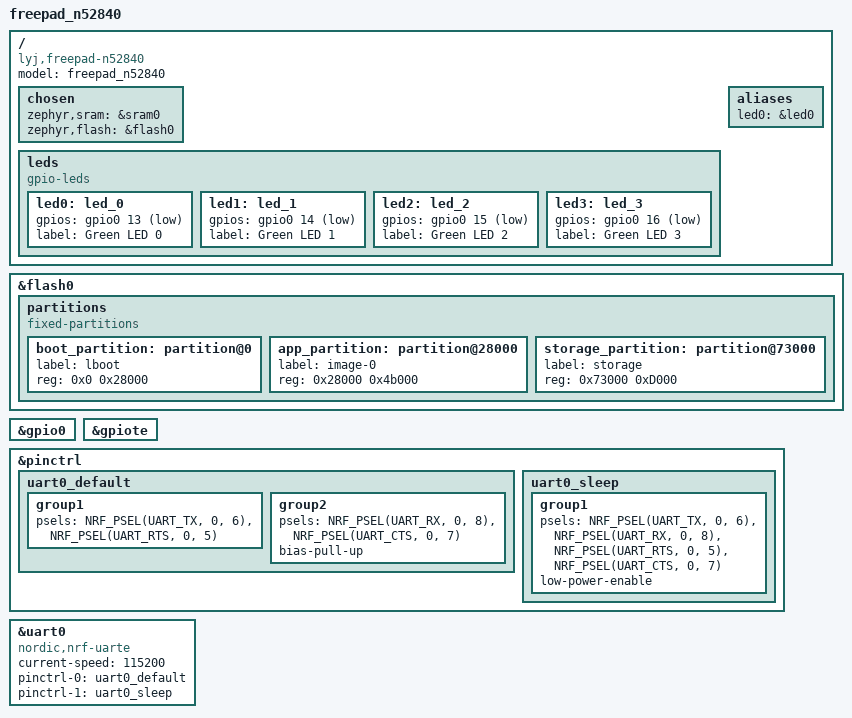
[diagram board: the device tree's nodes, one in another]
// Copyright (c) 2024 Nordic Semiconductor ASA
// SPDX-License-Identifier: Apache-2.0

/dts-v1/;
#include <nordic/nrf52840_qiaa.dtsi>

/ {
	model = "freepad_n52840";
	compatible = "lyj,freepad-n52840";

	chosen {
		zephyr,sram = &sram0;
		zephyr,flash = &flash0;
	};

	leds {
		compatible = "gpio-leds";
		led0: led_0 {
			gpios = <&gpio0 13 GPIO_ACTIVE_LOW>;
			label = "Green LED 0";
		};
		led1: led_1 {
			gpios = <&gpio0 14 GPIO_ACTIVE_LOW>;
			label = "Green LED 1";
		};
		led2: led_2 {
			gpios = <&gpio0 15 GPIO_ACTIVE_LOW>;
			label = "Green LED 2";
		};
		led3: led_3 {
			gpios = <&gpio0 16 GPIO_ACTIVE_LOW>;
			label = "Green LED 3";
		};
	};


	aliases {
		led0 = &led0;
	};
};


&flash0 {
	partitions {
		compatible = "fixed-partitions";
		#address-cells = <1>;
		#size-cells = <1>;

		boot_partition: partition@0 {
			label = "lboot";
			reg = <0x0 0x28000>;
		};
		app_partition: partition@28000 {
			label = "image-0";
			reg = <0x28000 0x4b000>;
		};
		storage_partition: partition@73000 {
			label = "storage";
			reg = <0x73000 0xD000>;
		};
	};
};

&gpio0 {
	status = "okay";
};

&gpiote {
	status = "okay";
};


&pinctrl {
	uart0_default: uart0_default {
		group1 {
			psels = <NRF_PSEL(UART_TX, 0, 6)>,
				<NRF_PSEL(UART_RTS, 0, 5)>;
		};
		group2 {
			psels = <NRF_PSEL(UART_RX, 0, 8)>,
				<NRF_PSEL(UART_CTS, 0, 7)>;
			bias-pull-up;
		};
	};

	uart0_sleep: uart0_sleep {
		group1 {
			psels = <NRF_PSEL(UART_TX, 0, 6)>,
				<NRF_PSEL(UART_RX, 0, 8)>,
				<NRF_PSEL(UART_RTS, 0, 5)>,
				<NRF_PSEL(UART_CTS, 0, 7)>;
			low-power-enable;
		};
	};
};

&uart0 {
	compatible = "nordic,nrf-uarte";
	status = "okay";
	current-speed = <115200>;
	pinctrl-0 = <&uart0_default>;
	pinctrl-1 = <&uart0_sleep>;
	pinctrl-names = "default", "sleep";
};
